# STM32WL3xx register map
File version: 1.0
Registers are 32-bit, read-write, reset 0x0 unless marked. A register's access mark holds for its fields unless they carry their own. Offsets are from the block's base; [hi:lo] are bit positions.

## RCC — Reset and clock control (RCC)
Base 0x48400000
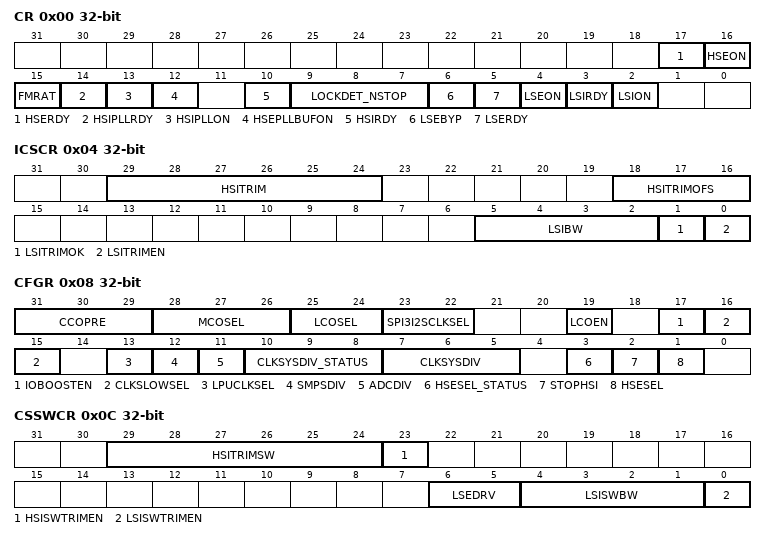
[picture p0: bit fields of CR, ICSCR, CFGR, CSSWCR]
0x00 CR — (@ 0x00000000) CR register
  [17] HSERDY
  [16] HSEON
    0=HSI (Enable HSI system clock); 1=HSE (Enable HSE system clock)
  [15] FMRAT
  [14] HSIPLLRDY
  [13] HSIPLLON
  [12] HSEPLLBUFON
  [10] HSIRDY
  [9:7] LOCKDET_NSTOP
  [6] LSEBYP
  [5] LSERDY
  [4] LSEON
  [3] LSIRDY
  [2] LSION
0x04 ICSCR — (@ 0x00000004) ICSCR register
  [29:24] HSITRIM, [18:16] HSITRIMOFS, [5:2] LSIBW, [1] LSITRIMOK, [0] LSITRIMEN
0x08 CFGR — (@ 0x00000008) CFGR register
  [31:29] CCOPRE
  [28:26] MCOSEL
  [25:24] LCOSEL
    0=NOCLOCK (LSCO output disabled, no clock on LSCO); 2=LSI (LSI selection as LSCO source); 3=LSE (LSE selection as LSCO source)
  [23:22] SPI3I2SCLKSEL
    0=ROOT_DIV (SPI3 I2S 16 MHz clock source selection bits); 1=ROOT (SPI3 I2S 32 MHz clock source selection bits); 2=RC64MPLL (SPI3 I2S 64 MHz clock source selection bits)
  [19] LCOEN
  [17] IOBOOSTEN
  [16:15] CLKSLOWSEL
    1=LSE (LSE selection for low speed clock); 2=LSI (Enable the LSI selection for low speed clock); 3=HSI64M_DIV2048 (HSI_64M divided by 2048 selection for low speed clock)
  [13] LPUCLKSEL
    0=CLK16M (LPUART Clock Selection 16 MHz); 1=CLKLSE (LPUART Clock Selection LSE source)
  [12] SMPSDIV
    0=DIV_2 (SMPS clock division 2 (SMPS clock is 8 MHz)); 1=DIV_4 (SMPS clock division 4 (SMPS clock is 4 MHz))
  [11] ADCDIV
  [10:8] CLKSYSDIV_STATUS
  [7:5] CLKSYSDIV
    0=DIV_1 (RC64MPLL not divided as SYSCLK); 1=DIV_2 (RC64MPLL divided by 2 as SYSCLK); 2=DIV_4 (RC64MPLL divided by 4 as SYSCLK); 3=DIV_8 (RC64MPLL divided by 8 as SYSCLK); 4=DIV_16 (RC64MPLL divided by 16 as SYSCLK); 5=DIV_32 (RC64MPLL divided by 32 as SYSCLK); 6=DIV_64 (RC64MPLL divided by 64 as SYSCLK)
  [3] HSESEL_STATUS
  [2] STOPHSI
  [1] HSESEL
0x0C CSSWCR — (@ 0x0000000C) CSSWCR register
  [29:24] HSITRIMSW
  [23] HSISWTRIMEN
  [6:5] LSEDRV
    0=LOW (Xtal mode lower driving capability); 1=MEDIUMLOW (Xtal mode medium low driving capability); 2=MEDIUMHIGH (Xtal mode medium high driving capability); 3=HIGH (Xtal mode higher driving capability)
  [4:1] LSISWBW
  [0] LSISWTRIMEN
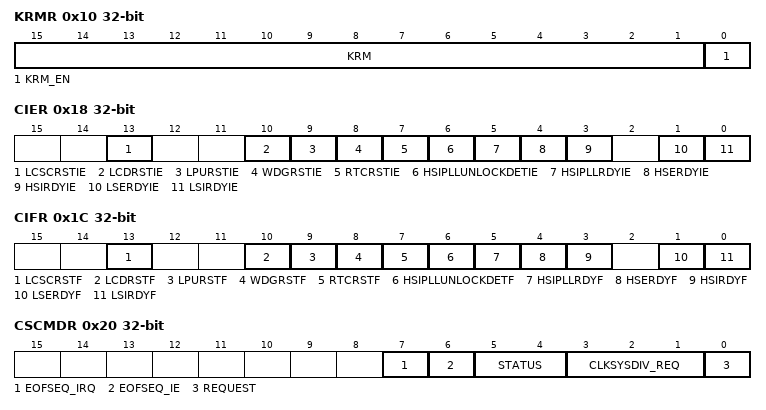
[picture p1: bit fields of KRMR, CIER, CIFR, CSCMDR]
0x10 KRMR — (@ 0x00000010) KRMR register
  [15:1] KRM, [0] KRM_EN
0x18 CIER — (@ 0x00000018) CIER register
  [13] LCSCRSTIE, [10] LCDRSTIE, [9] LPURSTIE, [8] WDGRSTIE, [7] RTCRSTIE, [6] HSIPLLUNLOCKDETIE, [5] HSIPLLRDYIE, [4] HSERDYIE, [3] HSIRDYIE, [1] LSERDYIE, [0] LSIRDYIE
0x1C CIFR — (@ 0x0000001C) CIFR register
  [13] LCSCRSTF, [10] LCDRSTF, [9] LPURSTF, [8] WDGRSTF, [7] RTCRSTF, [6] HSIPLLUNLOCKDETF, [5] HSIPLLRDYF, [4] HSERDYF, [3] HSIRDYF, [1] LSERDYF, [0] LSIRDYF
0x20 CSCMDR — (@ 0x00000020) CSCMDR register
  [7] EOFSEQ_IRQ
  [6] EOFSEQ_IE
  [5:4] STATUS
    0=IDLE (RC64MPLL Clock Switch Status IDLE); 1=ONGOING (RC64MPLL Clock Switch Status ONGOING); 2=DONE (RC64MPLL Clock Switch Status DONE)
  [3:1] CLKSYSDIV_REQ
    0=DIV_1 (RC64MPLL not divided as SYSCLK); 1=DIV_2 (RC64MPLL divided by 2 as SYSCLK); 2=DIV_4 (RC64MPLL divided by 4 as SYSCLK)
  [0] REQUEST
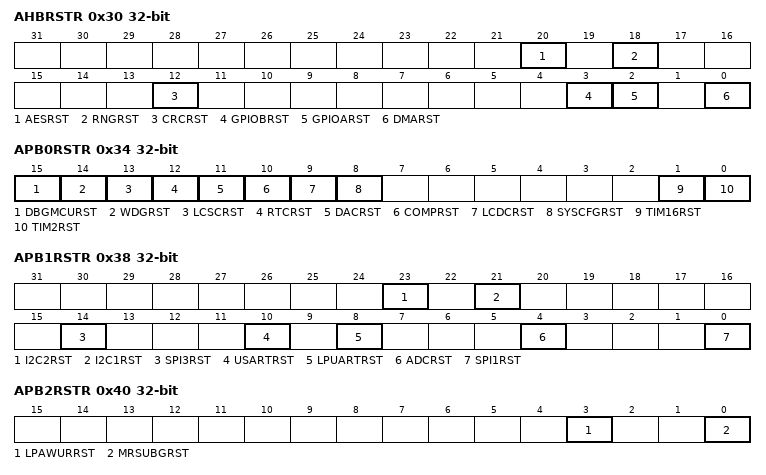
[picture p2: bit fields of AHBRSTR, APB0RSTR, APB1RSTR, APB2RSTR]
0x30 AHBRSTR — (@ 0x00000030) AHBRSTR register
  [20] AESRST, [18] RNGRST, [12] CRCRST, [3] GPIOBRST, [2] GPIOARST, [0] DMARST
0x34 APB0RSTR — (@ 0x00000034) APB0RSTR register
  [15] DBGMCURST, [14] WDGRST, [13] LCSCRST, [12] RTCRST, [11] DACRST, [10] COMPRST, [9] LCDCRST, [8] SYSCFGRST, [1] TIM16RST, [0] TIM2RST
0x38 APB1RSTR — (@ 0x00000038) APB1RSTR register
  [23] I2C2RST, [21] I2C1RST, [14] SPI3RST, [10] USARTRST, [8] LPUARTRST, [4] ADCRST, [0] SPI1RST
0x40 APB2RSTR — (@ 0x00000040) APB2RSTR register
  [3] LPAWURRST, [0] MRSUBGRST
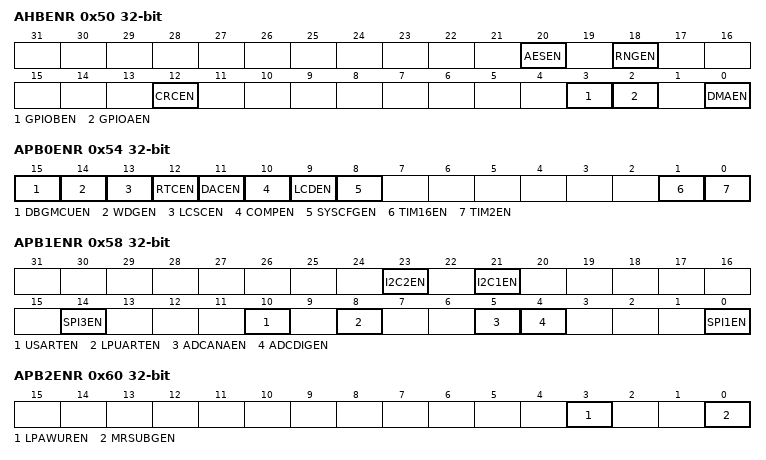
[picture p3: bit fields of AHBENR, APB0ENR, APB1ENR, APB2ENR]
0x50 AHBENR — (@ 0x00000050) AHBENR register
  [20] AESEN, [18] RNGEN, [12] CRCEN, [3] GPIOBEN, [2] GPIOAEN, [0] DMAEN
0x54 APB0ENR — (@ 0x00000054) APB0ENR register
  [15] DBGMCUEN, [14] WDGEN, [13] LCSCEN, [12] RTCEN, [11] DACEN, [10] COMPEN, [9] LCDEN, [8] SYSCFGEN, [1] TIM16EN, [0] TIM2EN
0x58 APB1ENR — (@ 0x00000058) APB1ENR register
  [23] I2C2EN, [21] I2C1EN, [14] SPI3EN, [10] USARTEN, [8] LPUARTEN, [5] ADCANAEN, [4] ADCDIGEN, [0] SPI1EN
0x60 APB2ENR — (@ 0x00000060) APB2ENR register
  [3] LPAWUREN, [0] MRSUBGEN
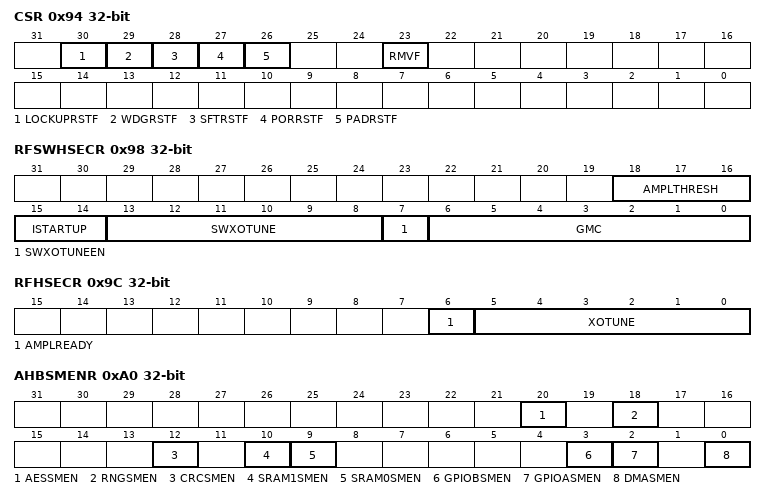
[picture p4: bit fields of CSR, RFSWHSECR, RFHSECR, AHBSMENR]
0x94 CSR — (@ 0x00000094) CSR register
  [30] LOCKUPRSTF, [29] WDGRSTF, [28] SFTRSTF, [27] PORRSTF, [26] PADRSTF, [23] RMVF
0x98 RFSWHSECR — (@ 0x00000098) RFSWHSECR register
  [18:16] AMPLTHRESH, [15:14] ISTARTUP, [13:8] SWXOTUNE, [7] SWXOTUNEEN, [6:0] GMC
0x9C RFHSECR — (@ 0x0000009C) RFHSECR register
  [6] AMPLREADY, [5:0] XOTUNE
0xA0 AHBSMENR — (@ 0x000000A0) AHBSMENR register
  [20] AESSMEN, [18] RNGSMEN, [12] CRCSMEN, [10] SRAM1SMEN, [9] SRAM0SMEN, [3] GPIOBSMEN, [2] GPIOASMEN, [0] DMASMEN
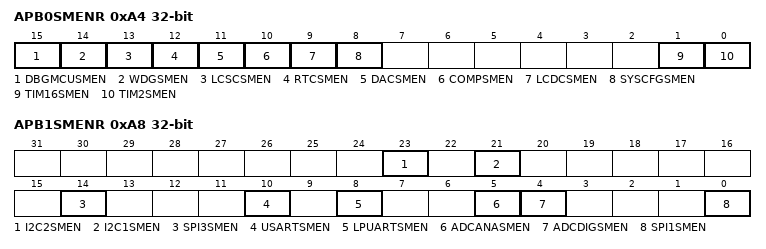
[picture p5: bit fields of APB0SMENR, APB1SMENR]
0xA4 APB0SMENR — (@ 0x000000A4) APB0SMENR register
  [15] DBGMCUSMEN, [14] WDGSMEN, [13] LCSCSMEN, [12] RTCSMEN, [11] DACSMEN, [10] COMPSMEN, [9] LCDCSMEN, [8] SYSCFGSMEN, [1] TIM16SMEN, [0] TIM2SMEN
0xA8 APB1SMENR — (@ 0x000000A8) APB1SMENR register
  [23] I2C2SMEN, [21] I2C1SMEN, [14] SPI3SMEN, [10] USARTSMEN, [8] LPUARTSMEN, [5] ADCANASMEN, [4] ADCDIGSMEN, [0] SPI1SMEN
